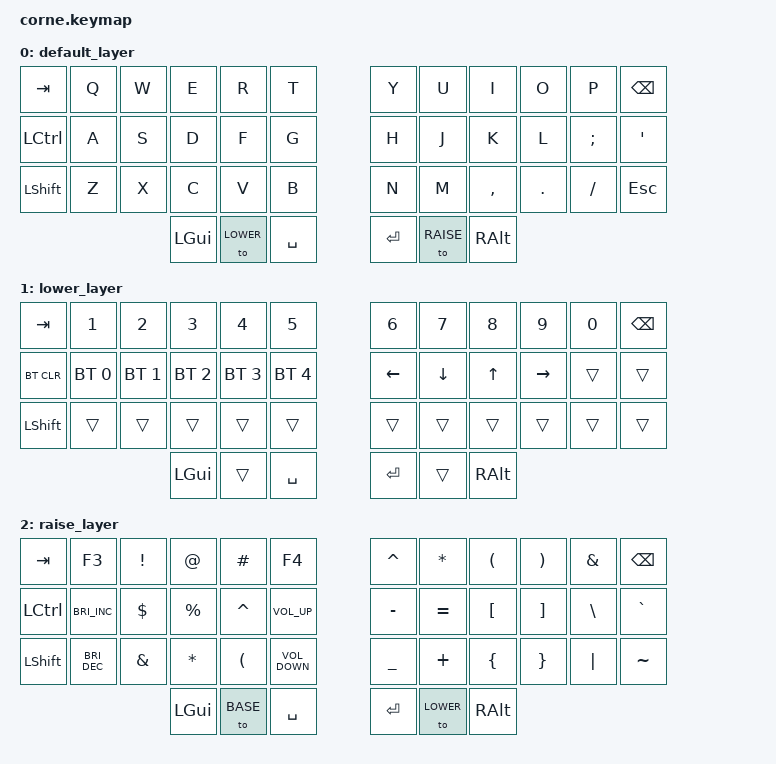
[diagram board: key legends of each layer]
#include <behaviors.dtsi>
#include <dt-bindings/zmk/keys.h>
#include <dt-bindings/zmk/bt.h>

#define BASE 0
#define LOWER 1
#define RAISE 2

/ {
  keymap {
    compatible = "zmk,keymap";

    default_layer {
      bindings = <
        &kp TAB &kp Q &kp W &kp E &kp R &kp T &kp Y &kp U &kp I &kp O &kp P &kp BACKSPACE &kp LEFT_CONTROL &kp A &kp S &kp D &kp F &kp G &kp H &kp J &kp K &kp L &kp SEMICOLON &kp SINGLE_QUOTE &kp LEFT_SHIFT &kp Z &kp X &kp C &kp V &kp B &kp N &kp M &kp COMMA &kp PERIOD &kp SLASH &kp ESCAPE &kp LEFT_GUI &to LOWER &kp SPACE &kp RETURN &to RAISE &kp RIGHT_ALT 
      >;
    };

    lower_layer {
                        bindings = <
   &kp TAB    &kp N1       &kp N2       &kp N3       &kp N4       &kp N5         &kp N6   &kp N7   &kp N8 &kp N9    &kp N0 &kp BSPC
   &bt BT_CLR &bt BT_SEL 0 &bt BT_SEL 1 &bt BT_SEL 2 &bt BT_SEL 3 &bt BT_SEL 4   &kp LEFT &kp DOWN &kp UP &kp RIGHT &trans &trans
   &kp LSHFT  &trans       &trans       &trans       &trans       &trans         &trans   &trans   &trans &trans    &trans &trans
                                    &kp LGUI     &trans       &kp SPACE      &kp RET  &trans   &kp RALT
                        >;
    };

    raise_layer {
      bindings = <
        &kp TAB &kp F3 &kp EXCLAMATION &kp AT_SIGN &kp HASH &kp F4 &kp CARET &kp ASTERISK &kp LEFT_PARENTHESIS &kp RIGHT_PARENTHESIS &kp AMPERSAND &kp BACKSPACE &kp LEFT_CONTROL &kp C_BRIGHTNESS_INC &kp DOLLAR &kp PERCENT &kp CARET &kp C_VOLUME_UP &kp MINUS &kp EQUAL &kp LEFT_BRACKET &kp RIGHT_BRACKET &kp BACKSLASH &kp GRAVE &kp LEFT_SHIFT &kp C_BRIGHTNESS_DEC &kp AMPERSAND &kp ASTERISK &kp LEFT_PARENTHESIS &kp C_VOLUME_DOWN &kp UNDERSCORE &kp PLUS &kp LEFT_BRACE &kp RIGHT_BRACE &kp PIPE &kp TILDE &kp LEFT_GUI &to BASE &kp SPACE &kp RETURN &to LOWER &kp RIGHT_ALT 
      >;
    };

  };
};
